# STM32H7S7xx register map
File version: 1.0
Registers are 32-bit, read-write, reset 0x0 unless marked. A register's access mark holds for its fields unless they carry their own. Offsets are from the block's base; [hi:lo] are bit positions; {n}, {i} and the like mark numbered series; 'fields as' and 'values as' point back to an identical list.

## RCC — Reset and Clock Control
Base 0x58024400
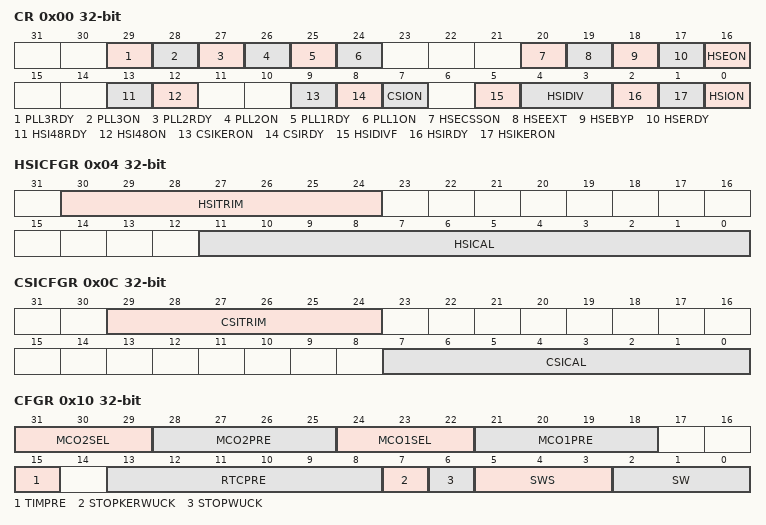
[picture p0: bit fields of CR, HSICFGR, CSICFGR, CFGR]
0x00 CR — RCC clock control register
  [29] PLL3RDY — System PLL3 clock ready flag
  [28] PLL3ON — System PLL3 clock enable
  [27] PLL2RDY — System PLL2 clock ready flag
  [26] PLL2ON — System PLL2 clock enable
  [25] PLL1RDY — System PLL1 clock ready flag
  [24] PLL1ON — System PLL1 clock enable
  [20] HSECSSON — HSE Clock security System enable
  [19] HSEEXT — External High Speed clock type in bypass mode
  [18] HSEBYP — External High Speed clock bypass
  [17] HSERDY — External High Speed clock ready flag
  [16] HSEON — External High Speed clock enable
  [13] HSI48RDY — HSI48 clock ready flag
  [12] HSI48ON — HSI48 clock enable clock enable
  [9] CSIKERON — Internal RC 4MHz oscillator clock enable in Stop mode
  [8] CSIRDY — The Internal RC 4MHz oscillator clock ready
  [7] CSION — The Internal RC 4MHz oscillator clock enable
  [5] HSIDIVF — HSI Divider flag
  [4:3] HSIDIV — Internal High Speed clock divider selection
    0=DIV_1; 1=DIV_2; 2=DIV_4; 3=DIV_8
  [2] HSIRDY — Internal High Speed clock ready flag
  [1] HSIKERON — Internal High Speed clock enable in Stop mode
  [0] HSION — Internal High Speed clock enable
0x04 HSICFGR — HSI clock calibration register
  [30:24] HSITRIM — HSITRIM[6:0] bits
  [11:0] HSICAL — HSICAL[11:0] bits
0x08 CRRCR — Clock recovery RC register
  [9:0] HSI48CAL — HSI48CAL[9:0] bits
0x0C CSICFGR — CSI clock calibration register
  [29:24] CSITRIM — CSITRIM[5:0] bits
  [7:0] CSICAL — CSICAL[7:0] bits
0x10 CFGR — RCC clock configuration register
  [31:29] MCO2SEL — MCO2SEL [2:0] bits (MCO2 clock output selection)
  [28:25] MCO2PRE — MCO2 configuration
  [24:22] MCO1SEL — MCO1SEL [2:0] bits (MCO1 clock output selection)
  [21:18] MCO1PRE — MCO1 configuration
  [15] TIMPRE — TIMPRE configuration
    0=TWICE; 1=FOUR_TIMES
  [13:8] RTCPRE — RTCPRE[5:0] bits (HSE division factor for RTC clock)
    0=NOCLOCK; {v}=HSE_DIV_{v} (v=2..63)
  [7] STOPKERWUCK — Kernel Clock Selection after a Wake Up from Stop
    0=HSI; 1=CSI
  [6] STOPWUCK — Wake Up from stop and CSS backup clock selection
    0=HSI; 1=CSI
  [5:3] SWS — SWS[2:0] bits (System clock switch status)
    0=HSI (HSI used as system clock); 1=CSI (CSI used as system clock); 2=HSE (HSE used as system clock); 3=PLL1 (PLL1 used as system clock)
  [2:0] SW — SW[2:0] bits (System clock switch)
    0=HSI; 1=CSI; 2=HSE; 3=PLL1
0x18 CDCFGR — RCC CPU domain configuration register
  [3:0] CPRE — CPRE[3:0] bits
    0=DIV_1; 8=DIV_2; 9=DIV_4; 10=DIV_8; 11=DIV_16; 12=DIV_64; 13=DIV_128; 14=DIV_256; 15=DIV_512
0x1C BMCFGR — RCC Bus matrix configuration register
  [3:0] BMPRE — BMPRE[3:0] bits
    values as CDCFGR.CPRE
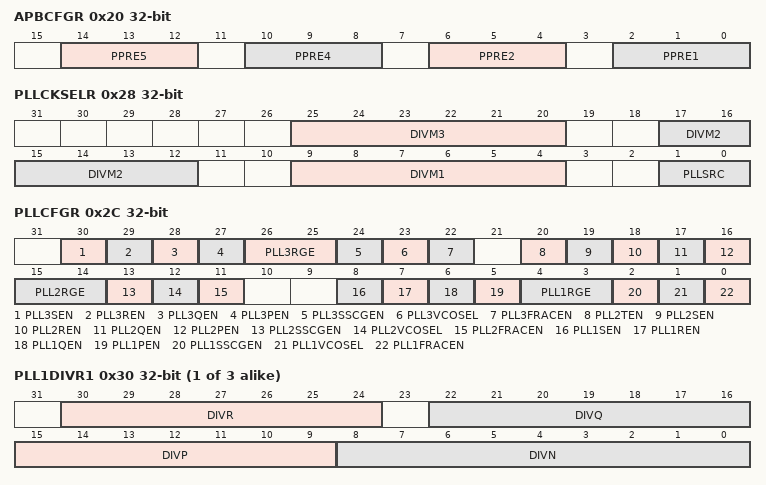
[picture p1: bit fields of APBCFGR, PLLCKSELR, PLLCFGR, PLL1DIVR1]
0x20 APBCFGR — RCC APB clock configuration register
  [all] fields
    0=DIV_1; 4=DIV_2; 5=DIV_4; 6=DIV_8; 7=DIV_16
  [14:12] PPRE5 — PPRE5[2:0] bits
  [10:8] PPRE4 — PPRE4[2:0] bits
  [6:4] PPRE2 — PPRE2[2:0] bits
  [2:0] PPRE1 — PPRE1[2:0] bits
0x28 PLLCKSELR — RCC PLLs clock source selection register
  [25:20] DIVM3 — DIVM3[5:0] bits
  [17:12] DIVM2 — DIVM2[5:0] bits
  [9:4] DIVM1 — DIVM1[5:0] bits
  [1:0] PLLSRC — DIVMx and PLLs clock source selection
    0=HSI; 1=CSI; 2=HSE; 3=NONE
0x2C PLLCFGR — RCC PLLs configuration register
  [30] PLL3SEN — PLL3 DIVS divider output enable
  [29] PLL3REN — PLL3 DIVR divider output enable
  [28] PLL3QEN — PLL3 DIVQ divider output enable
  [27] PLL3PEN — PLL3 DIVP divider output enable
  [26:25] PLL3RGE — PLL3RGE[1:0] bits: PLL3 input frequency range
  [24] PLL3SSCGEN — PLL3 Spread Spectrum Clock Generator enable
  [23] PLL3VCOSEL — PLL3 VCO selection
  [22] PLL3FRACEN — PLL3 fractional latch enable
  [20] PLL2TEN — PLL2 DIVT divider output enable
  [19] PLL2SEN — PLL2 DIVS divider output enable
  [18] PLL2REN — PLL2 DIVR divider output enable
  [17] PLL2QEN — PLL2 DIVQ divider output enable
  [16] PLL2PEN — PLL2 DIVP divider output enable
  [15:14] PLL2RGE — PLL2RGE[1:0] bits: PLL2 input frequency range
  [13] PLL2SSCGEN — PLL2 Spread Spectrum Clock Generator enable
  [12] PLL2VCOSEL — PLL2 VCO selection
  [11] PLL2FRACEN — PLL2 fractional latch enable
  [8] PLL1SEN — PLL1 DIVS divider output enable
  [7] PLL1REN — PLL1 DIVR divider output enable
  [6] PLL1QEN — PLL1 DIVQ divider output enable
  [5] PLL1PEN — PLL1 DIVP divider output enable
  [4:3] PLL1RGE — PLL1RGE[1:0] bits: PLL1 input frequency range
    0=PLLINPUTRANGE_1_2; 1=PLLINPUTRANGE_2_4; 2=PLLINPUTRANGE_4_8; 3=PLLINPUTRANGE_8_16
  [2] PLL1SSCGEN — PLL1 Spread Spectrum Clock Generator enable
  [1] PLL1VCOSEL — PLL1 VCO selection
    0=WIDE (VCO output range: 400 to 1600 MHz); 1=MEDIUM (VCO output range: 150 to 420 MHz)
  [0] PLL1FRACEN — PLL1 fractional latch enable
{0x28+8i} PLL{i}DIVR1 (i=1..3) — RCC PLL{i} dividers configuration register 1
  [30:24] DIVR — DIVR{i}[6:0] bits: PLL{i} DIVR division factor
  [22:16] DIVQ — DIVQ{i}[6:0] bits: PLL{i} DIVQ division factor
  [15:9] DIVP — DIVP{i}[6:0] bits: PLL{i} DIVP division factor
  [8:0] DIVN — DIVN{i}[8:0] bits: PLL{i} DIVN division factor
{0x2C+8i} PLL{i}FRACR (i=1..3) — RCC PLL{i} fractional divider configuration register
  [15:3] FRACN — FRACN[12:0] bits
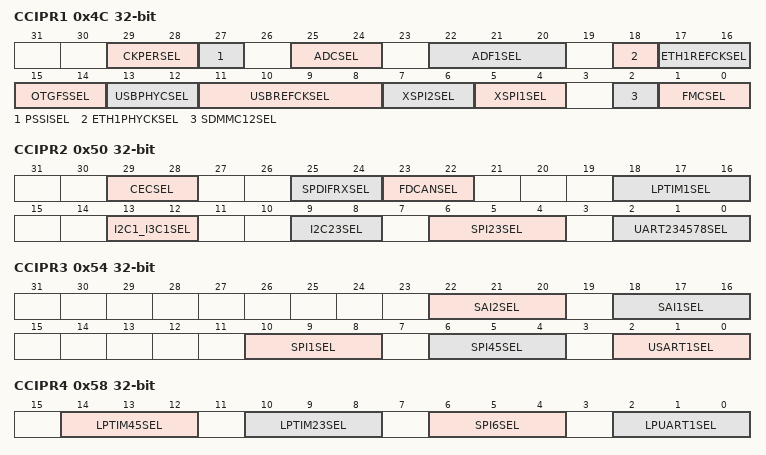
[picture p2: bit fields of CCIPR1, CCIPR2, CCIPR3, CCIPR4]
0x4C CCIPR1 — RCC AHB peripherals kernel clock configuration register
  [29:28] CKPERSEL
    0=HSI; 1=CSI; 2=HSE; 3=CLKSOURCE
  [27] PSSISEL
    0=PLL3R; 1=CLKP
  [25:24] ADCSEL
    0=PLL2P; 1=PLL3R; 2=CLKP; 3=CLKSOURCE
  [22:20] ADF1SEL
    0=HCLK; 1=PLL2P; 2=PLL3P; 3=I2S_CKIN; 4=CSI; 5=HSI; 7=CLKSOURCE
  [18] ETH1PHYCKSEL
    0=HSE; 1=PLL3S
  [17:16] ETH1REFCKSEL
    0=RMII; 1=HSE; 2=FB; 3=CLKSOURCE
  [15:14] OTGFSSEL
    0=HSI48; 3=CLK48; 2=HSE; 1=PLL3Q
  [13:12] USBPHYCSEL
    3=DISABLE; 0=HSE; 1=HSE_DIV_2; 2=PLL3Q
  [11:8] USBREFCKSEL
    3=CLKSOURCE_16M; 8=CLKSOURCE_19_2M; 9=CLKSOURCE_20M; 10=CLKSOURCE_24M; 14=CLKSOURCE_26M; 11=CLKSOURCE_32M; 15=CLKSOURCE
  [7:6] XSPI2SEL
  [5:4] XSPI1SEL
  [2] SDMMC12SEL
    0=PLL2S; 1=PLL2T
  [1:0] FMCSEL
    0=HCLK; 1=PLL1Q; 2=PLL2R; 3=HSI
0x50 CCIPR2 — RCC APB1 peripherals kernel clock configuration register
  [29:28] CECSEL
    0=LSE; 1=LSI; 2=CSI_DIV_122; 3=CLKSOURCE
  [25:24] SPDIFRXSEL
    0=PLL1Q; 1=PLL2R; 2=PLL3R; 3=HSI
  [23:22] FDCANSEL
    0=HSE; 1=PLL1Q; 2=PLL2Q; 3=CLKSOURCE
  [18:16] LPTIM1SEL
  [13:12] I2C1_I3C1SEL
    0=PCLK1; 1=PLL3R; 2=HSI; 3=CSI
  [9:8] I2C23SEL
  [6:4] SPI23SEL
  [2:0] UART234578SEL
0x54 CCIPR3 — RCC APB2 peripherals kernel clock configuration register
  [22:20] SAI2SEL, [18:16] SAI1SEL, [10:8] SPI1SEL, [6:4] SPI45SEL, [2:0] USART1SEL
0x58 CCIPR4 — RCC APB4/APB5 peripherals kernel clock configuration register
  [14:12] LPTIM45SEL
  [10:8] LPTIM23SEL
  [6:4] SPI6SEL
  [2:0] LPUART1SEL
    0=PCLK4; 1=PLL2Q; 2=PLL3Q; 3=HSI; 4=CSI; 5=LSE; 7=CLKSOURCE
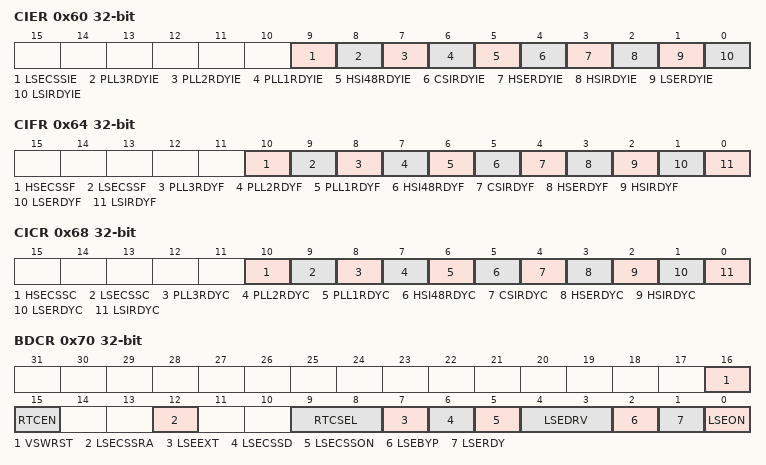
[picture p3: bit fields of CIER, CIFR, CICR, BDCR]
0x60 CIER — RCC clock interrupt enable register
  [9] LSECSSIE, [8] PLL3RDYIE, [7] PLL2RDYIE, [6] PLL1RDYIE, [5] HSI48RDYIE, [4] CSIRDYIE, [3] HSERDYIE, [2] HSIRDYIE, [1] LSERDYIE, [0] LSIRDYIE
0x64 CIFR — RCC clock interrupt flag register
  [10] HSECSSF, [9] LSECSSF, [8] PLL3RDYF, [7] PLL2RDYF, [6] PLL1RDYF, [5] HSI48RDYF, [4] CSIRDYF, [3] HSERDYF, [2] HSIRDYF, [1] LSERDYF, [0] LSIRDYF
0x68 CICR — RCC clock interrupt clear register
  [10] HSECSSC, [9] LSECSSC, [8] PLL3RDYC, [7] PLL2RDYC, [6] PLL1RDYC, [5] HSI48RDYC, [4] CSIRDYC, [3] HSERDYC, [2] HSIRDYC, [1] LSERDYC, [0] LSIRDYC
0x70 BDCR — RCC backup domain control register
  [16] VSWRST
  [15] RTCEN
  [12] LSECSSRA
  [9:8] RTCSEL
    0=NONE; 1=LSE; 2=LSI; 3=HSE
  [7] LSEEXT
  [6] LSECSSD
  [5] LSECSSON
  [4:3] LSEDRV
    0=LOW; 1=MEDIUMLOW; 2=MEDIUMHIGH; 3=HIGH
  [2] LSEBYP
  [1] LSERDY
  [0] LSEON
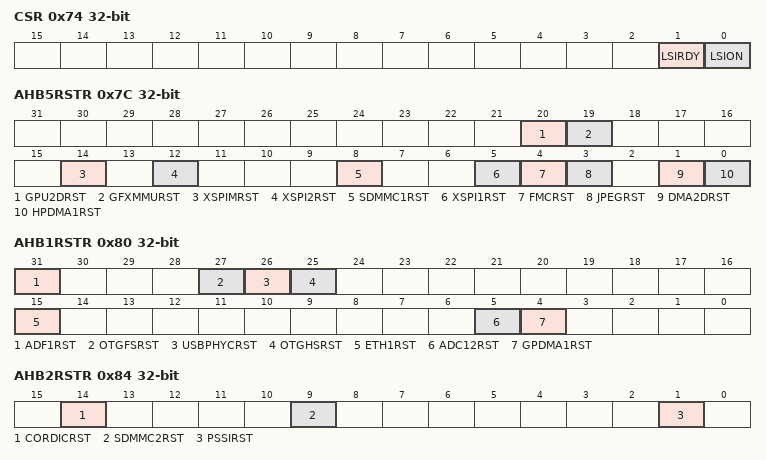
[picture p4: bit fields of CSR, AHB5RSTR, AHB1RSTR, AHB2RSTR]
0x74 CSR — RCC clock control & status register
  [1] LSIRDY, [0] LSION
0x7C AHB5RSTR — RCC AHB5 peripheral reset register
  [20] GPU2DRST, [19] GFXMMURST, [14] XSPIMRST, [12] XSPI2RST, [8] SDMMC1RST, [5] XSPI1RST, [4] FMCRST, [3] JPEGRST, [1] DMA2DRST, [0] HPDMA1RST
0x80 AHB1RSTR — RCC AHB1 peripheral reset register
  [31] ADF1RST, [27] OTGFSRST, [26] USBPHYCRST, [25] OTGHSRST, [15] ETH1RST, [5] ADC12RST, [4] GPDMA1RST
0x84 AHB2RSTR — RCC AHB2 peripheral reset register
  [14] CORDICRST, [9] SDMMC2RST, [1] PSSIRST
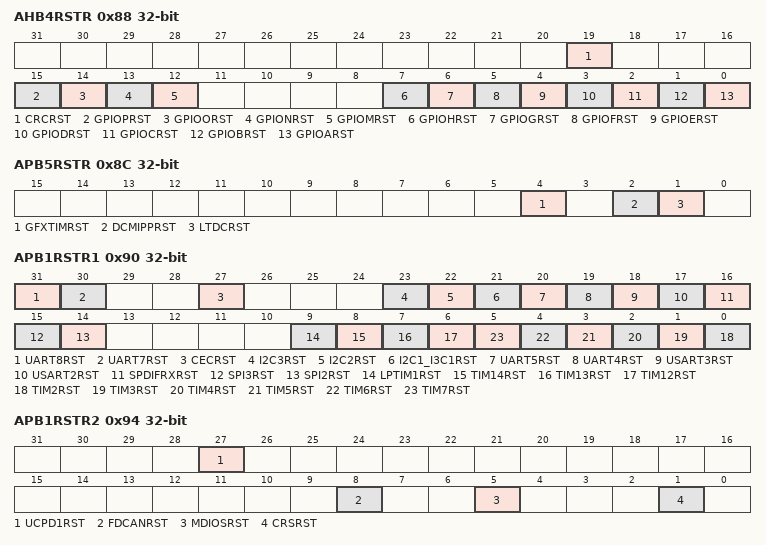
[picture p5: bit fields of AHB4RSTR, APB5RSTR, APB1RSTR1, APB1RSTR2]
0x88 AHB4RSTR — RCC AHB4 peripheral reset register
  [19] CRCRST, [15] GPIOPRST, [14] GPIOORST, [13] GPIONRST, [12] GPIOMRST, [7] GPIOHRST, [6] GPIOGRST, [5] GPIOFRST, [4] GPIOERST, [3] GPIODRST, [2] GPIOCRST, [1] GPIOBRST, [0] GPIOARST
0x8C APB5RSTR — RCC APB5 peripheral reset register
  [4] GFXTIMRST, [2] DCMIPPRST, [1] LTDCRST
0x90 APB1RSTR1 — RCC APB1 peripheral reset register 1
  [31] UART8RST, [30] UART7RST, [27] CECRST, [23] I2C3RST, [22] I2C2RST, [21] I2C1_I3C1RST, [20] UART5RST, [19] UART4RST, [18] USART3RST, [17] USART2RST, [16] SPDIFRXRST, [15] SPI3RST, [14] SPI2RST, [9] LPTIM1RST, [8] TIM14RST, [7] TIM13RST, [6] TIM12RST, [n-2] TIM{n}RST (n=2..7)
0x94 APB1RSTR2 — RCC APB1 peripheral reset register 2
  [27] UCPD1RST, [8] FDCANRST, [5] MDIOSRST, [1] CRSRST
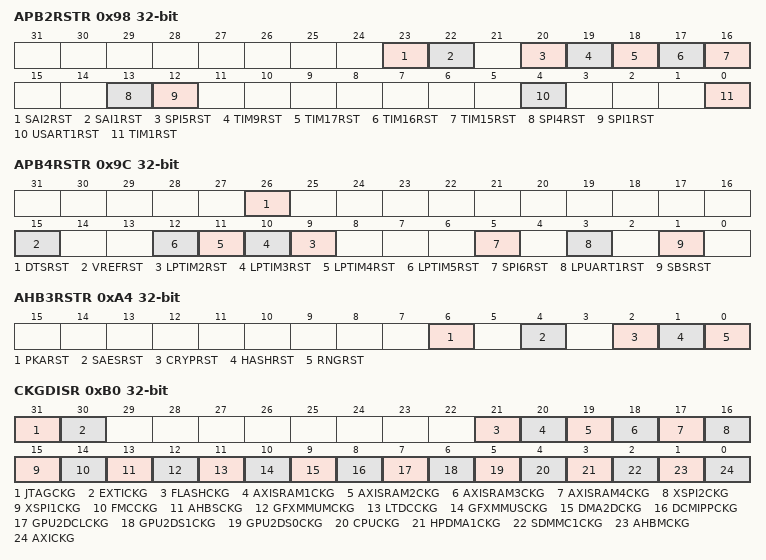
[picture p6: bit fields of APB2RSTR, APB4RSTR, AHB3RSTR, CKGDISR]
0x98 APB2RSTR — RCC APB2 peripheral reset register
  [23] SAI2RST, [22] SAI1RST, [20] SPI5RST, [19] TIM9RST, [18] TIM17RST, [17] TIM16RST, [16] TIM15RST, [13] SPI4RST, [12] SPI1RST, [4] USART1RST, [0] TIM1RST
0x9C APB4RSTR — RCC APB4 peripheral reset register
  [26] DTSRST, [15] VREFRST, [n+7] LPTIM{n}RST (n=2..5), [5] SPI6RST, [3] LPUART1RST, [1] SBSRST
0xA4 AHB3RSTR — RCC AHB3 peripheral reset register
  [6] PKARST, [4] SAESRST, [2] CRYPRST, [1] HASHRST, [0] RNGRST
0xB0 CKGDISR — RCC AXI clocks gating disable register
  [31] JTAGCKG, [30] EXTICKG, [21] FLASHCKG, [21-n] AXISRAM{n}CKG (n=1..4), [16] XSPI2CKG, [15] XSPI1CKG, [14] FMCCKG, [13] AHBSCKG, [12] GFXMMUMCKG, [11] LTDCCKG, [10] GFXMMUSCKG, [9] DMA2DCKG, [8] DCMIPPCKG, [7] GPU2DCLCKG, [6] GPU2DS1CKG, [5] GPU2DS0CKG, [4] CPUCKG, [3] HPDMA1CKG, [2] SDMMC1CKG, [1] AHBMCKG, [0] AXICKG
0xC0 PLL1DIVR2 — RCC PLL1 dividers configuration register 2
  [2:0] DIVS — DIVS1[2:0] bits: PLL1 DIVS division factor
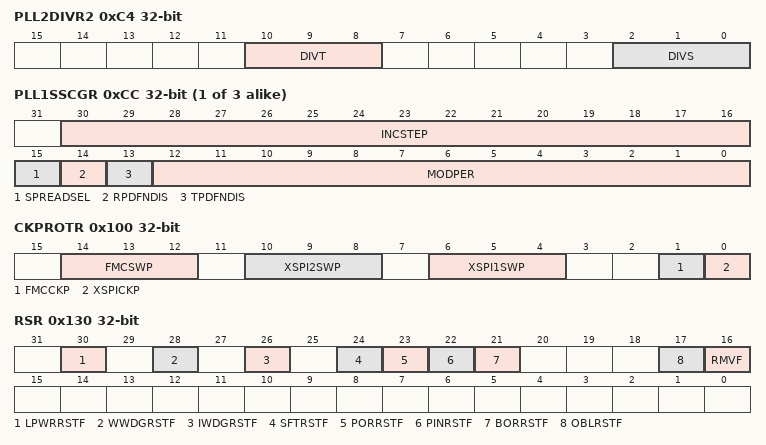
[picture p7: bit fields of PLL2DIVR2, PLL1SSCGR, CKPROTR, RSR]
0xC4 PLL2DIVR2 — RCC PLL2 dividers configuration register 2
  [10:8] DIVT — DIVT2[2:0] bits: PLL2 DIVT division factor
  [2:0] DIVS — DIVS2[2:0] bits: PLL2 DIVS division factor
0xC8 PLL3DIVR2 — RCC PLL3 dividers configuration register 2
  [2:0] DIVS — DIVS3[2:0] bits: PLL3 DIVS division factor
{0xC8+4i} PLL{i}SSCGR (i=1..3) — RCC PLL{i} spread spectrum clock generator register
  [30:16] INCSTEP — INCSTEP[14:0] bits: Modulation Depth Adjustment
  [15] SPREADSEL
    0=CENTER (PLL center spread spectrum selection); 1=DOWN (PLL down spread spectrum selection)
  [14] RPDFNDIS
  [13] TPDFNDIS
  [12:0] MODPER — MODPER[12:0] bits: Modulation Period Adjustment
0x100 CKPROTR — RCC clock protection register
  [14:12] FMCSWP
    0=NEUTRAL; 1=HCLK5; 2=PLL1Q; 3=PLL2R; 4=HSI; 5=HCLK_DIV4
  [10:8] XSPI2SWP
    0=NEUTRAL; 1=HCLK5; 2=PLL2S; 3=PLL2T; 4=HCLK_DIV4
  [6:4] XSPI1SWP
    0=NEUTRAL; 1=HCLK5; 2=PLL2S; 3=PLL2T; 4=HCLK_DIV4
  [1] FMCCKP
  [0] XSPICKP
0x130 RSR — RCC reset status register
  [30] LPWRRSTF, [28] WWDGRSTF, [26] IWDGRSTF, [24] SFTRSTF, [23] PORRSTF, [22] PINRSTF, [21] BORRSTF, [17] OBLRSTF, [16] RMVF
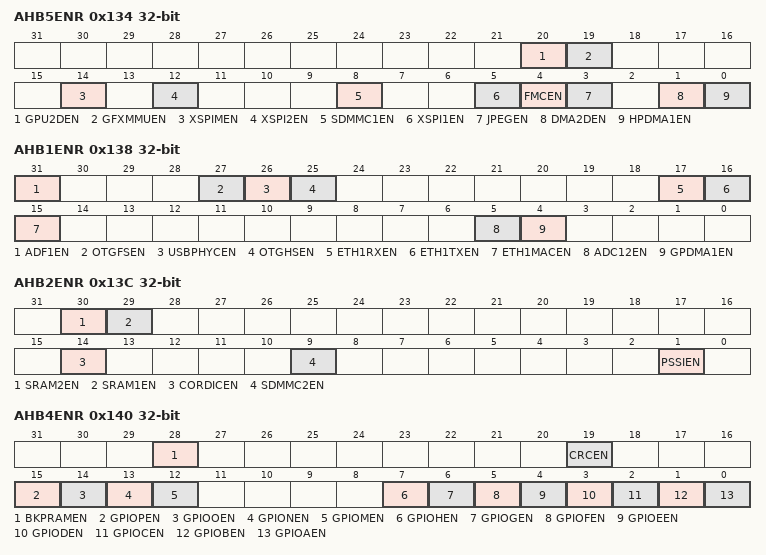
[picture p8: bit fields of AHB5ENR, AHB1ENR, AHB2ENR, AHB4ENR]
0x134 AHB5ENR — RCC AHB5 peripheral clocks enable register
  [20] GPU2DEN, [19] GFXMMUEN, [14] XSPIMEN, [12] XSPI2EN, [8] SDMMC1EN, [5] XSPI1EN, [4] FMCEN, [3] JPEGEN, [1] DMA2DEN, [0] HPDMA1EN
0x138 AHB1ENR — RCC AHB1 peripheral clocks enable register
  [31] ADF1EN, [27] OTGFSEN, [26] USBPHYCEN, [25] OTGHSEN, [17] ETH1RXEN, [16] ETH1TXEN, [15] ETH1MACEN, [5] ADC12EN, [4] GPDMA1EN
0x13C AHB2ENR — RCC AHB2 peripheral clocks enable register
  [30] SRAM2EN, [29] SRAM1EN, [14] CORDICEN, [9] SDMMC2EN, [1] PSSIEN
0x140 AHB4ENR — RCC AHB4 peripheral clocks enable register
  [28] BKPRAMEN, [19] CRCEN, [15] GPIOPEN, [14] GPIOOEN, [13] GPIONEN, [12] GPIOMEN, [7] GPIOHEN, [6] GPIOGEN, [5] GPIOFEN, [4] GPIOEEN, [3] GPIODEN, [2] GPIOCEN, [1] GPIOBEN, [0] GPIOAEN
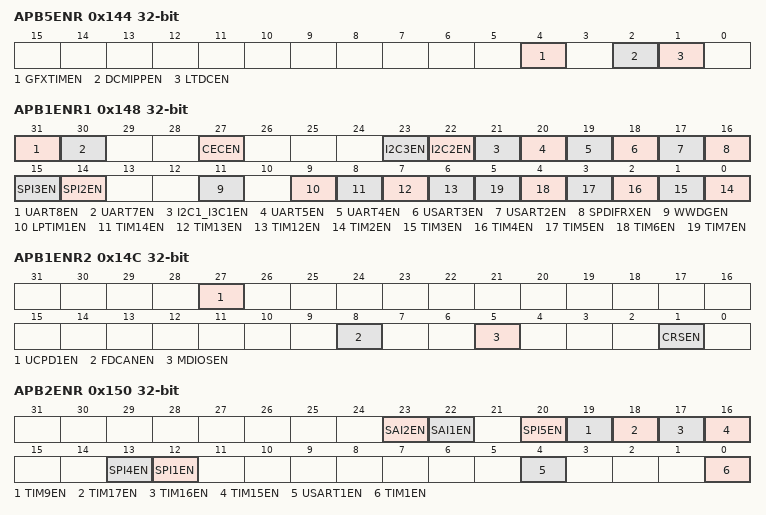
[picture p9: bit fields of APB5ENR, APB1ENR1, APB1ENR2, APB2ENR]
0x144 APB5ENR — RCC APB5 peripheral clocks enable register
  [4] GFXTIMEN, [2] DCMIPPEN, [1] LTDCEN
0x148 APB1ENR1 — RCC APB1 peripheral clocks enable register 1
  [31] UART8EN, [30] UART7EN, [27] CECEN, [23] I2C3EN, [22] I2C2EN, [21] I2C1_I3C1EN, [20] UART5EN, [19] UART4EN, [18] USART3EN, [17] USART2EN, [16] SPDIFRXEN, [15] SPI3EN, [14] SPI2EN, [11] WWDGEN, [9] LPTIM1EN, [8] TIM14EN, [7] TIM13EN, [6] TIM12EN, [n-2] TIM{n}EN (n=2..7)
0x14C APB1ENR2 — RCC APB1 peripheral clocks enable register 2
  [27] UCPD1EN, [8] FDCANEN, [5] MDIOSEN, [1] CRSEN
0x150 APB2ENR — RCC APB2 peripheral clocks enable register
  [23] SAI2EN, [22] SAI1EN, [20] SPI5EN, [19] TIM9EN, [18] TIM17EN, [17] TIM16EN, [16] TIM15EN, [13] SPI4EN, [12] SPI1EN, [4] USART1EN, [0] TIM1EN
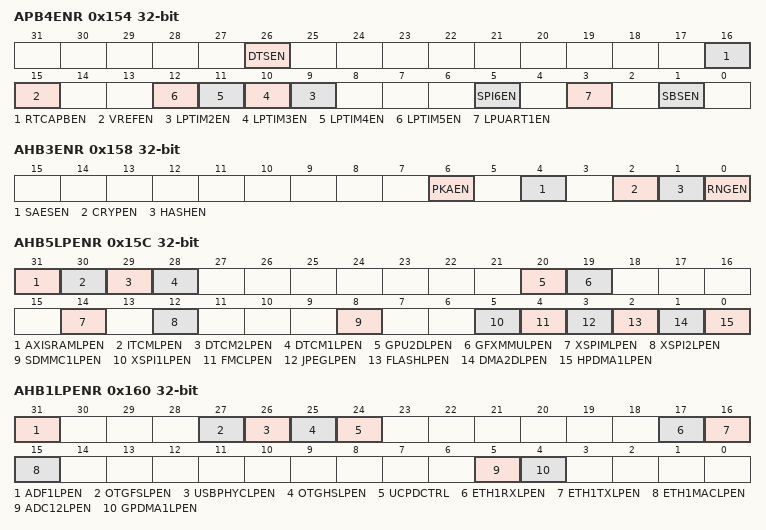
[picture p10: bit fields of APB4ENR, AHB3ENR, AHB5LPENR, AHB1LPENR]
0x154 APB4ENR — RCC APB4 peripheral clocks enable register
  [26] DTSEN, [16] RTCAPBEN, [15] VREFEN, [n+7] LPTIM{n}EN (n=2..5), [5] SPI6EN, [3] LPUART1EN, [1] SBSEN
0x158 AHB3ENR — RCC AHB3 peripheral clocks enable register
  [6] PKAEN, [4] SAESEN, [2] CRYPEN, [1] HASHEN, [0] RNGEN
0x15C AHB5LPENR — RCC AHB5 peripheral sleep clocks enable register
  [31] AXISRAMLPEN, [30] ITCMLPEN, [29] DTCM2LPEN, [28] DTCM1LPEN, [20] GPU2DLPEN, [19] GFXMMULPEN, [14] XSPIMLPEN, [12] XSPI2LPEN, [8] SDMMC1LPEN, [5] XSPI1LPEN, [4] FMCLPEN, [3] JPEGLPEN, [2] FLASHLPEN, [1] DMA2DLPEN, [0] HPDMA1LPEN
0x160 AHB1LPENR — RCC AHB1 peripheral sleep clocks enable register
  [31] ADF1LPEN, [27] OTGFSLPEN, [26] USBPHYCLPEN, [25] OTGHSLPEN, [24] UCPDCTRL, [17] ETH1RXLPEN, [16] ETH1TXLPEN, [15] ETH1MACLPEN, [5] ADC12LPEN, [4] GPDMA1LPEN
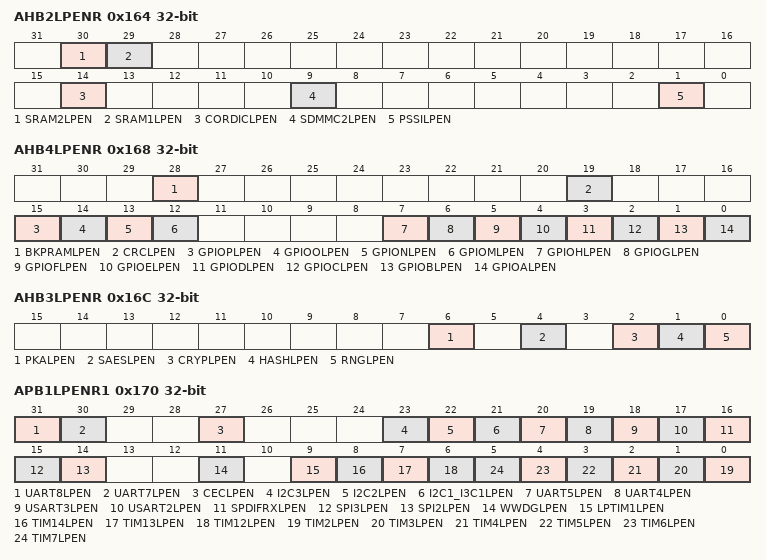
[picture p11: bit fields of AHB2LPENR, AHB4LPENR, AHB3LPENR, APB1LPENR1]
0x164 AHB2LPENR — RCC AHB2 peripheral sleep clocks enable register
  [30] SRAM2LPEN, [29] SRAM1LPEN, [14] CORDICLPEN, [9] SDMMC2LPEN, [1] PSSILPEN
0x168 AHB4LPENR — RCC AHB4 peripheral sleep clocks enable register
  [28] BKPRAMLPEN, [19] CRCLPEN, [15] GPIOPLPEN, [14] GPIOOLPEN, [13] GPIONLPEN, [12] GPIOMLPEN, [7] GPIOHLPEN, [6] GPIOGLPEN, [5] GPIOFLPEN, [4] GPIOELPEN, [3] GPIODLPEN, [2] GPIOCLPEN, [1] GPIOBLPEN, [0] GPIOALPEN
0x16C AHB3LPENR — RCC AHB3 peripheral sleep clocks enable register
  [6] PKALPEN, [4] SAESLPEN, [2] CRYPLPEN, [1] HASHLPEN, [0] RNGLPEN
0x170 APB1LPENR1 — RCC APB1 peripheral sleep clocks enable register 1
  [31] UART8LPEN, [30] UART7LPEN, [27] CECLPEN, [23] I2C3LPEN, [22] I2C2LPEN, [21] I2C1_I3C1LPEN, [20] UART5LPEN, [19] UART4LPEN, [18] USART3LPEN, [17] USART2LPEN, [16] SPDIFRXLPEN, [15] SPI3LPEN, [14] SPI2LPEN, [11] WWDGLPEN, [9] LPTIM1LPEN, [8] TIM14LPEN, [7] TIM13LPEN, [6] TIM12LPEN, [n-2] TIM{n}LPEN (n=2..7)
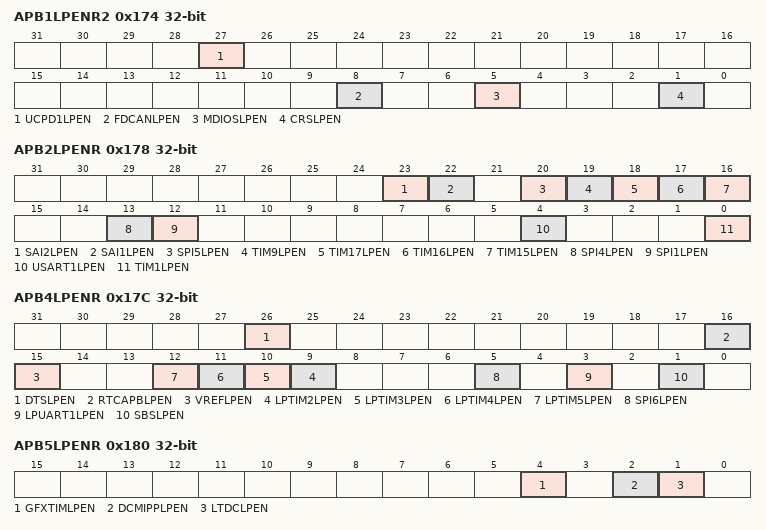
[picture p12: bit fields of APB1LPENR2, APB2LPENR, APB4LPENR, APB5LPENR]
0x174 APB1LPENR2 — RCC APB1 peripheral sleep clocks enable register 2
  [27] UCPD1LPEN, [8] FDCANLPEN, [5] MDIOSLPEN, [1] CRSLPEN
0x178 APB2LPENR — RCC APB2 peripheral sleep clocks enable register
  [23] SAI2LPEN, [22] SAI1LPEN, [20] SPI5LPEN, [19] TIM9LPEN, [18] TIM17LPEN, [17] TIM16LPEN, [16] TIM15LPEN, [13] SPI4LPEN, [12] SPI1LPEN, [4] USART1LPEN, [0] TIM1LPEN
0x17C APB4LPENR — RCC APB4 peripheral sleep clocks enable register
  [26] DTSLPEN, [16] RTCAPBLPEN, [15] VREFLPEN, [n+7] LPTIM{n}LPEN (n=2..5), [5] SPI6LPEN, [3] LPUART1LPEN, [1] SBSLPEN
0x180 APB5LPENR — RCC APB5 peripheral sleep clocks enable register
  [4] GFXTIMLPEN, [2] DCMIPPLPEN, [1] LTDCLPEN
